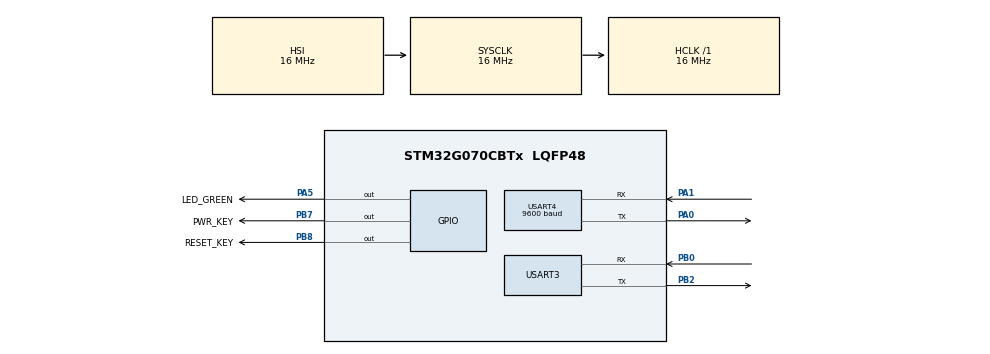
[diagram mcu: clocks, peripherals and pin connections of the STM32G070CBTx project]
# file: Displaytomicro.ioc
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Mcu.Family=STM32G0
Mcu.Name=STM32G070CBTx
Mcu.Package=LQFP48
NVIC.USART3_4_IRQn=true\:0\:0\:false\:false\:true\:true\:true\:true
PA0.Mode=Asynchronous
PA0.Signal=USART4_TX
PA1.Mode=Asynchronous
PA1.Signal=USART4_RX
PA13.Mode=Serial_Wire
PA13.Signal=SYS_SWDIO
PA14-BOOT0.Mode=Serial_Wire
PA14-BOOT0.Signal=SYS_SWCLK
PA5.GPIO_Label=LED_GREEN
PA5.PinState=GPIO_PIN_RESET
PA5.Signal=GPIO_Output
PB0.Mode=Asynchronous
PB0.Signal=USART3_RX
PB2.Mode=Asynchronous
PB2.Signal=USART3_TX
PB7.GPIO_Label=PWR_KEY
PB7.GPIO_PuPd=GPIO_PULLDOWN
PB7.Signal=GPIO_Output
PB8.GPIO_Label=RESET_KEY
PB8.GPIO_PuPd=GPIO_PULLUP
PB8.Signal=GPIO_Output
PC14-OSC32_IN\ (PC14).Mode=LSE-External-Oscillator
PC14-OSC32_IN\ (PC14).Signal=RCC_OSC32_IN
PC15-OSC32_OUT\ (PC15).Mode=LSE-External-Oscillator
PC15-OSC32_OUT\ (PC15).Signal=RCC_OSC32_OUT
ProjectManager.HeapSize=0x200
ProjectManager.StackSize=0x400
ProjectManager.TargetToolchain=STM32CubeIDE
RCC.AHBFreq_Value=16000000
RCC.CortexFreq_Value=16000000
RCC.EXTERNAL_CLOCK_VALUE=48000
RCC.HCLKFreq_Value=16000000
RCC.HSE_VALUE=8000000
RCC.HSI_VALUE=16000000
RCC.SYSCLKFreq_VALUE=16000000
RCC.VCOOutputFreq_Value=128000000
USART3.VirtualMode-Asynchronous=VM_ASYNC
USART4.BaudRate=9600
USART4.VirtualMode-Asynchronous=VM_ASYNC
board=custom

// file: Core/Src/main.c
/* USER CODE BEGIN Header */
/**
  ******************************************************************************
  * @file           : main.c
  * @brief          : Main program body
  ******************************************************************************
  * @attention
  *
  * Copyright (c) 2024 STMicroelectronics.
  * All rights reserved.
  *
  * This software is licensed under terms that can be found in the LICENSE file
  * in the root directory of this software component.
  * If no LICENSE file comes with this software, it is provided AS-IS.
  *
  ******************************************************************************
  */
/* USER CODE END Header */
#include "main.h"

/* USER CODE BEGIN Includes */
#include <string.h>
#include <stdio.h>
#include <stdbool.h>

/* USER CODE END Includes */

/* USER CODE BEGIN PD */
#define LED_Pin GPIO_PIN_5
#define LED_GPIO_Port GPIOA

/* USER CODE END PD */

UART_HandleTypeDef huart3;
UART_HandleTypeDef huart4;

/* USER CODE BEGIN PV */
uint8_t txData[] = {0x47, 0x01, 0x37};
uint8_t data[70] = {0};
HAL_StatusTypeDef Inverter_receive_status ;

/* USER CODE END PV */

void SystemClock_Config(void);
static void MX_GPIO_Init(void);
static void MX_USART3_UART_Init(void);
static void MX_USART4_UART_Init(void);

int main(void)
{

  /* MCU Configuration--------------------------------------------------------*/

  /* Reset of all peripherals, Initializes the Flash interface and the Systick. */
  HAL_Init();

  /* Configure the system clock */
  SystemClock_Config();

  /* Initialize all configured peripherals */
  MX_GPIO_Init();
  MX_USART3_UART_Init();
  MX_USART4_UART_Init();

  /* Infinite loop */
  while (1)
  {

    /* USER CODE BEGIN 3 */
	  HAL_StatusTypeDef Inverter_receive_status=HAL_TIMEOUT;
	  while(Inverter_receive_status!=HAL_OK){
		  HAL_UART_Transmit_IT(&huart4, txData, sizeof(txData));
	  	  Inverter_receive_status=HAL_UART_Receive(&huart4, data, 70,2000);
	  	  HAL_GPIO_TogglePin(LED_GPIO_Port, LED_Pin);
	  }

  }
  /* USER CODE END 3 */

}

void SystemClock_Config(void)
{
  RCC_OscInitTypeDef RCC_OscInitStruct = {0};
  RCC_ClkInitTypeDef RCC_ClkInitStruct = {0};

  /** Configure the main internal regulator output voltage
  */
  HAL_PWREx_ControlVoltageScaling(PWR_REGULATOR_VOLTAGE_SCALE1);

  /** Initializes the RCC Oscillators according to the specified parameters
  * in the RCC_OscInitTypeDef structure.
  */
  RCC_OscInitStruct.OscillatorType = RCC_OSCILLATORTYPE_HSI;
  RCC_OscInitStruct.HSIState = RCC_HSI_ON;
  RCC_OscInitStruct.HSIDiv = RCC_HSI_DIV1;
  RCC_OscInitStruct.HSICalibrationValue = RCC_HSICALIBRATION_DEFAULT;
  RCC_OscInitStruct.PLL.PLLState = RCC_PLL_NONE;
  if (HAL_RCC_OscConfig(&RCC_OscInitStruct) != HAL_OK)
  {
    Error_Handler();
  }

  /** Initializes the CPU, AHB and APB buses clocks
  */
  RCC_ClkInitStruct.ClockType = RCC_CLOCKTYPE_HCLK|RCC_CLOCKTYPE_SYSCLK
                              |RCC_CLOCKTYPE_PCLK1;
  RCC_ClkInitStruct.SYSCLKSource = RCC_SYSCLKSOURCE_HSI;
  RCC_ClkInitStruct.AHBCLKDivider = RCC_SYSCLK_DIV1;
  RCC_ClkInitStruct.APB1CLKDivider = RCC_HCLK_DIV1;

  if (HAL_RCC_ClockConfig(&RCC_ClkInitStruct, FLASH_LATENCY_0) != HAL_OK)
  {
    Error_Handler();
  }
}

static void MX_USART3_UART_Init(void)
{

  huart3.Instance = USART3;
  huart3.Init.BaudRate = 115200;
  huart3.Init.WordLength = UART_WORDLENGTH_8B;
  huart3.Init.StopBits = UART_STOPBITS_1;
  huart3.Init.Parity = UART_PARITY_NONE;
  huart3.Init.Mode = UART_MODE_TX_RX;
  huart3.Init.HwFlowCtl = UART_HWCONTROL_NONE;
  huart3.Init.OverSampling = UART_OVERSAMPLING_16;
  huart3.Init.OneBitSampling = UART_ONE_BIT_SAMPLE_DISABLE;
  huart3.Init.ClockPrescaler = UART_PRESCALER_DIV1;
  huart3.AdvancedInit.AdvFeatureInit = UART_ADVFEATURE_NO_INIT;
  if (HAL_UART_Init(&huart3) != HAL_OK)
  {
    Error_Handler();
  }

}

static void MX_USART4_UART_Init(void)
{

  huart4.Instance = USART4;
  huart4.Init.BaudRate = 9600;
  huart4.Init.WordLength = UART_WORDLENGTH_8B;
  huart4.Init.StopBits = UART_STOPBITS_1;
  huart4.Init.Parity = UART_PARITY_NONE;
  huart4.Init.Mode = UART_MODE_TX_RX;
  huart4.Init.HwFlowCtl = UART_HWCONTROL_NONE;
  huart4.Init.OverSampling = UART_OVERSAMPLING_16;
  huart4.Init.OneBitSampling = UART_ONE_BIT_SAMPLE_DISABLE;
  huart4.Init.ClockPrescaler = UART_PRESCALER_DIV1;
  huart4.AdvancedInit.AdvFeatureInit = UART_ADVFEATURE_NO_INIT;
  if (HAL_UART_Init(&huart4) != HAL_OK)
  {
    Error_Handler();
  }

}

static void MX_GPIO_Init(void)
{
  GPIO_InitTypeDef GPIO_InitStruct = {0};

  /* GPIO Ports Clock Enable */
  __HAL_RCC_GPIOC_CLK_ENABLE();
  __HAL_RCC_GPIOA_CLK_ENABLE();
  __HAL_RCC_GPIOB_CLK_ENABLE();

  /*Configure GPIO pin Output Level */
  HAL_GPIO_WritePin(LED_GREEN_GPIO_Port, LED_GREEN_Pin, GPIO_PIN_RESET);

  /*Configure GPIO pin Output Level */
  HAL_GPIO_WritePin(GPIOB, PWR_KEY_Pin|RESET_KEY_Pin, GPIO_PIN_RESET);

  /*Configure GPIO pin : LED_GREEN_Pin */
  GPIO_InitStruct.Pin = LED_GREEN_Pin;
  GPIO_InitStruct.Mode = GPIO_MODE_OUTPUT_PP;
  GPIO_InitStruct.Pull = GPIO_NOPULL;
  GPIO_InitStruct.Speed = GPIO_SPEED_FREQ_LOW;
  HAL_GPIO_Init(LED_GREEN_GPIO_Port, &GPIO_InitStruct);

  /*Configure GPIO pin : PWR_KEY_Pin */
  GPIO_InitStruct.Pin = PWR_KEY_Pin;
  GPIO_InitStruct.Mode = GPIO_MODE_OUTPUT_PP;
  GPIO_InitStruct.Pull = GPIO_PULLDOWN;
  GPIO_InitStruct.Speed = GPIO_SPEED_FREQ_LOW;
  HAL_GPIO_Init(PWR_KEY_GPIO_Port, &GPIO_InitStruct);

  /*Configure GPIO pin : RESET_KEY_Pin */
  GPIO_InitStruct.Pin = RESET_KEY_Pin;
  GPIO_InitStruct.Mode = GPIO_MODE_OUTPUT_PP;
  GPIO_InitStruct.Pull = GPIO_PULLUP;
  GPIO_InitStruct.Speed = GPIO_SPEED_FREQ_LOW;
  HAL_GPIO_Init(RESET_KEY_GPIO_Port, &GPIO_InitStruct);

}

void Error_Handler(void)
{
  __disable_irq();
  while (1)
  {
  }
}
